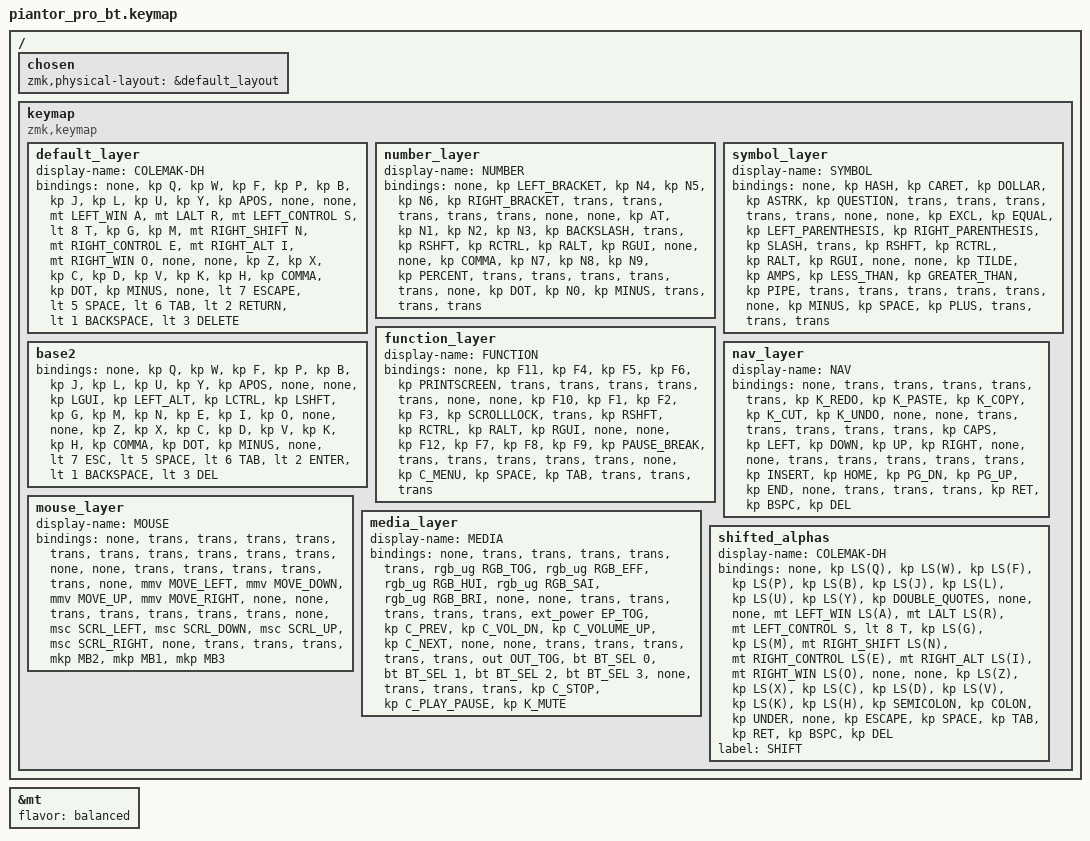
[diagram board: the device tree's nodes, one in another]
/*
 * Copyright (c) 2020 The ZMK Contributors
 *
 * SPDX-License-Identifier: MIT
 */

#include <behaviors.dtsi>
#include <dt-bindings/zmk/bt.h>
#include <dt-bindings/zmk/ext_power.h>
#include <dt-bindings/zmk/keys.h>
#include <dt-bindings/zmk/outputs.h>
#include <dt-bindings/zmk/pointing.h>
#include <dt-bindings/zmk/rgb.h>

&mt { flavor = "balanced"; };

/ {
    chosen { zmk,physical-layout = &default_layout; };
};

/ {
    keymap {
        compatible = "zmk,keymap";

        default_layer {
            display-name = "COLEMAK-DH";

            // --------------------------------------------------------------------------------
            // |  TAB |  Q  |  W  |  E  |  R  |  T  |  Y  |  U   |  I  |  O  |  P  | BSPC |
            // | CTRL |  A  |  S  |  D  |  F  |  G  |  H  |  J   |  K  |  L  |  ;  |  '   |
            // | SHFT |  Z  |  X  |  C  |  V  |  B  |  N  |  M   |  ,  |  .  |  /  | ESC  |
            //                    | GUI | LWR | SPC | ENT | RSE  | ALT |

            bindings = <
&none  &kp Q  &kp W  &kp F  &kp P  &kp B  &kp J  &kp L  &kp U  &kp Y  &kp APOS  &none  &none  &mt LEFT_WIN A  &mt LALT R  &mt LEFT_CONTROL S  &lt 8 T  &kp G  &kp M  &mt RIGHT_SHIFT N  &mt RIGHT_CONTROL E  &mt RIGHT_ALT I  &mt RIGHT_WIN O  &none  &none  &kp Z  &kp X  &kp C  &kp D  &kp V  &kp K  &kp H  &kp COMMA  &kp DOT  &kp MINUS  &none  &lt 7 ESCAPE  &lt 5 SPACE  &lt 6 TAB  &lt 2 RETURN  &lt 1 BACKSPACE  &lt 3 DELETE
            >;
        };

        number_layer {
            display-name = "NUMBER";

            // -----------------------------------------------------------------------------------------
            // |  TAB |  1  |  2  |  3  |  4  |  5    |  6  |  7  |  8  |  9  |  0  | BSPC |
            // | CTRL | BT1 | BT2 | BT3 | BT4 | BT5   | LFT | DWN |  UP | RGT |     |      |
            // | SHFT | BTCR| RGB | RST | BOOT| Unlock|     |     |     |     |     |      |
            //                    | GUI |     | SPC   | ENT |     | ALT |

            bindings = <
&none  &kp LEFT_BRACKET  &kp N4  &kp N5  &kp N6  &kp RIGHT_BRACKET  &trans  &trans  &trans  &trans  &trans  &none  &none  &kp AT  &kp N1  &kp N2  &kp N3  &kp BACKSLASH  &trans  &kp RSHFT  &kp RCTRL  &kp RALT  &kp RGUI  &none  &none  &kp COMMA  &kp N7  &kp N8  &kp N9  &kp PERCENT  &trans  &trans  &trans  &trans  &trans  &none  &kp DOT  &kp N0  &kp MINUS  &trans  &trans  &trans
            >;
        };

        symbol_layer {
            display-name = "SYMBOL";
            bindings = <
&none  &kp HASH  &kp CARET  &kp DOLLAR  &kp ASTRK  &kp QUESTION  &trans  &trans  &trans  &trans  &trans  &none  &none  &kp EXCL  &kp EQUAL  &kp LEFT_PARENTHESIS  &kp RIGHT_PARENTHESIS  &kp SLASH  &trans  &kp RSHFT  &kp RCTRL  &kp RALT  &kp RGUI  &none  &none  &kp TILDE  &kp AMPS  &kp LESS_THAN  &kp GREATER_THAN  &kp PIPE  &trans  &trans  &trans  &trans  &trans  &none  &kp MINUS  &kp SPACE  &kp PLUS  &trans  &trans  &trans
            >;
        };

        function_layer {
            display-name = "FUNCTION";
            bindings = <
&none  &kp F11  &kp F4  &kp F5  &kp F6  &kp PRINTSCREEN  &trans  &trans  &trans  &trans  &trans  &none  &none  &kp F10  &kp F1  &kp F2  &kp F3  &kp SCROLLLOCK  &trans  &kp RSHFT  &kp RCTRL  &kp RALT  &kp RGUI  &none  &none  &kp F12  &kp F7  &kp F8  &kp F9  &kp PAUSE_BREAK  &trans  &trans  &trans  &trans  &trans  &none  &kp C_MENU  &kp SPACE  &kp TAB  &trans  &trans  &trans
            >;
        };

        base2 {
            bindings = <
&none  &kp Q  &kp W  &kp F  &kp P  &kp B  &kp J  &kp L  &kp U  &kp Y  &kp APOS  &none  &none  &kp LGUI  &kp LEFT_ALT  &kp LCTRL  &kp LSHFT  &kp G  &kp M  &kp N  &kp E  &kp I  &kp O  &none  &none  &kp Z  &kp X  &kp C  &kp D  &kp V  &kp K  &kp H  &kp COMMA  &kp DOT  &kp MINUS  &none  &lt 7 ESC  &lt 5 SPACE  &lt 6 TAB  &lt 2 ENTER  &lt 1 BACKSPACE  &lt 3 DEL
            >;
        };

        nav_layer {
            display-name = "NAV";
            bindings = <
&none  &trans  &trans  &trans  &trans  &trans  &kp K_REDO  &kp K_PASTE  &kp K_COPY  &kp K_CUT  &kp K_UNDO  &none  &none  &trans  &trans  &trans  &trans  &trans  &kp CAPS  &kp LEFT  &kp DOWN  &kp UP  &kp RIGHT  &none  &none  &trans  &trans  &trans  &trans  &trans  &kp INSERT  &kp HOME  &kp PG_DN  &kp PG_UP  &kp END  &none  &trans  &trans  &trans  &kp RET  &kp BSPC  &kp DEL
            >;
        };

        mouse_layer {
            display-name = "MOUSE";
            bindings = <
&none  &trans  &trans  &trans  &trans  &trans  &trans  &trans  &trans  &trans  &trans  &none  &none  &trans  &trans  &trans  &trans  &trans  &none  &mmv MOVE_LEFT  &mmv MOVE_DOWN  &mmv MOVE_UP  &mmv MOVE_RIGHT  &none  &none  &trans  &trans  &trans  &trans  &trans  &none  &msc SCRL_LEFT  &msc SCRL_DOWN  &msc SCRL_UP  &msc SCRL_RIGHT  &none  &trans  &trans  &trans  &mkp MB2  &mkp MB1  &mkp MB3
            >;
        };

        media_layer {
            display-name = "MEDIA";
            bindings = <
&none  &trans  &trans  &trans  &trans  &trans  &rgb_ug RGB_TOG  &rgb_ug RGB_EFF  &rgb_ug RGB_HUI  &rgb_ug RGB_SAI  &rgb_ug RGB_BRI  &none  &none  &trans  &trans  &trans  &trans  &trans  &ext_power EP_TOG  &kp C_PREV  &kp C_VOL_DN  &kp C_VOLUME_UP  &kp C_NEXT  &none  &none  &trans  &trans  &trans  &trans  &trans  &out OUT_TOG  &bt BT_SEL 0  &bt BT_SEL 1  &bt BT_SEL 2  &bt BT_SEL 3  &none  &trans  &trans  &trans  &kp C_STOP  &kp C_PLAY_PAUSE  &kp K_MUTE
            >;
        };

        shifted_alphas {
            display-name = "COLEMAK-DH";
            bindings = <
&none  &kp LS(Q)  &kp LS(W)  &kp LS(F)  &kp LS(P)  &kp LS(B)  &kp LS(J)  &kp LS(L)  &kp LS(U)  &kp LS(Y)  &kp DOUBLE_QUOTES  &none  &none  &mt LEFT_WIN LS(A)  &mt LALT LS(R)  &mt LEFT_CONTROL S  &lt 8 T  &kp LS(G)  &kp LS(M)  &mt RIGHT_SHIFT LS(N)  &mt RIGHT_CONTROL LS(E)  &mt RIGHT_ALT LS(I)  &mt RIGHT_WIN LS(O)  &none  &none  &kp LS(Z)  &kp LS(X)  &kp LS(C)  &kp LS(D)  &kp LS(V)  &kp LS(K)  &kp LS(H)  &kp SEMICOLON  &kp COLON  &kp UNDER  &none  &kp ESCAPE  &kp SPACE  &kp TAB  &kp RET  &kp BSPC  &kp DEL
            >;

            label = "SHIFT";
        };
    };
};
